# BL808 register map
File version: 0.1
Registers are access not given, no defined reset value unless marked. A register's access mark holds for its fields unless they carry their own. Offsets are from the block's base; [hi:lo] are bit positions.

## CSI
Base 0x3001A000
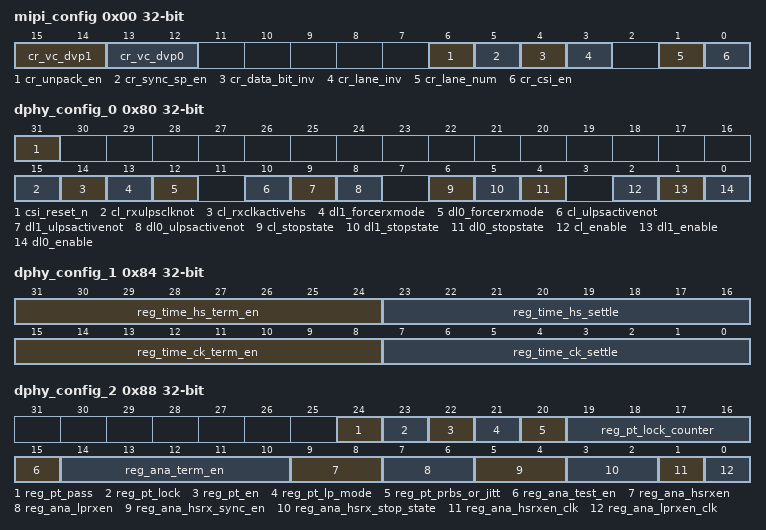
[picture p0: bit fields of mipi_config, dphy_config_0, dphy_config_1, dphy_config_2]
0x00 mipi_config
  [15:14] cr_vc_dvp1 rw — Virtual Channel number for DVP port 1
  [13:12] cr_vc_dvp0 rw — Virtual Channel number for DVP port 0
  [6] cr_unpack_en rw — Enable signal for data-unpack function 1'b0: Unpack disabled, DVP output is 8-bit valid (byte-in-byte-out) 1'b1: Unpack enabled, DVP output format depends on packet data type (RAW 8/10/12/14)
  [5] cr_sync_sp_en rw — Enable signal for sync short packets (FS/FE/LS/LE) to be received into gnr_data_buf
  [4] cr_data_bit_inv rw — Controls the bit ordering of PPI I/F data byte, which should be set to little-endian (MSB [7]) 1'b0: Not inversed 1'b1: Inversed
  [3] cr_lane_inv rw — Lane inverse 1'b0: Lane0 & Lane1 NOT inversed 1'b1: Lane0 & Lane1 inversed
  [1] cr_lane_num rw — Lane number configuration 1'b0: 1-lane MIPI RX 1'b1: 2-lane MIPI RX
  [0] cr_csi_en rw — Enable signal of MIPI receiving function
0x10 csi_int_status
  [5:0] csi_int_status ro — [5]: PHY HS SoT Sync Error [4]: PHY HS SoT Error [3]: CRC Error [2]: ECC Error [1]: Lane Merging Error [0]: Generic Packet Interrupt
0x14 csi_int_mask
  [5:0] csi_int_mask rw — [5]: PHY HS SoT Sync Error [4]: PHY HS SoT Error [3]: CRC Error [2]: ECC Error [1]: Lane Merging Error [0]: Generic Packet Interrupt
0x18 csi_int_clear
  [5:0] csi_int_clear write-once — [5]: PHY HS SoT Sync Error [4]: PHY HS SoT Error [3]: CRC Error [2]: ECC Error [1]: Lane Merging Error [0]: Generic Packet Interrupt
0x1C csi_int_enable
  [5:0] csi_int_enable rw — [5]: PHY HS SoT Sync Error [4]: PHY HS SoT Error [3]: CRC Error [2]: ECC Error [1]: Lane Merging Error [0]: Generic Packet Interrupt
0x20 gnr_buf_status
  [3:0] st_gnr_fifo_cnt ro — Generic Packet FIFO count
0x24 gnr_buf_rdata ro
  [31:0] gnr_buf_rdata — Generic Packet FIFO read port
0x80 dphy_config_0
  [31] csi_reset_n rw — MIPI CSI D-PHY reset pin
  [15] cl_rxulpsclknot ro — Receiver Ultra-Low Power State on clock lane
  [14] cl_rxclkactivehs ro — Receiver clock active
  [13] dl1_forcerxmode rw — Force Lane1 to Re-Initialize
  [12] dl0_forcerxmode rw — Force Lane0 to Re-Initialize
  [10] cl_ulpsactivenot ro — Clock lane is NOT in the ULP state
  [9] dl1_ulpsactivenot ro — Data lane1 is NOT in the ULP state
  [8] dl0_ulpsactivenot ro — Data lane0 is NOT in the ULP state
  [6] cl_stopstate ro — Clock lane is in Stop state
  [5] dl1_stopstate ro — Data lane1 is in Stop state
  [4] dl0_stopstate ro — Data lane0 is in Stop state
  [2] cl_enable rw — Clock lane enable
  [1] dl1_enable rw — Data lane1 enable
  [0] dl0_enable rw — Data lane0 enable
0x84 dphy_config_1 rw
  [31:24] reg_time_hs_term_en — MIPI CSI D-PHY control register - reg_time_hs_term_en (2x T_datarate), txclkesc: 40M, datarate: 800Mbps
  [23:16] reg_time_hs_settle — MIPI CSI D-PHY control register - reg_time_hs_settle (2x T_datarate)
  [15:8] reg_time_ck_term_en — MIPI CSI D-PHY control register - reg_time_ck_term_en (tx_clk_esc)
  [7:0] reg_time_ck_settle — MIPI CSI D-PHY control register - reg_time_ck_settle (tx_clk_esc)
0x88 dphy_config_2
  [24] reg_pt_pass ro — MIPI CSI D-PHY control register - reg_pt_pass
  [23] reg_pt_lock ro — MIPI CSI D-PHY control register - reg_pt_lock
  [22] reg_pt_en rw — MIPI CSI D-PHY control register - reg_pt_en
  [21] reg_pt_lp_mode rw — MIPI CSI D-PHY control register - reg_pt_lp_mode
  [20] reg_pt_prbs_or_jitt rw — MIPI CSI D-PHY control register - reg_pt_prbs_or_jitt
  [19:16] reg_pt_lock_counter rw — MIPI CSI D-PHY control register - reg_pt_lock_counter
  [15] reg_ana_test_en rw — MIPI CSI D-PHY control register - reg_ana_test_en
  [14:10] reg_ana_term_en rw — MIPI CSI D-PHY control register - reg_ana_term_en
  [9:8] reg_ana_hsrxen rw — MIPI CSI D-PHY control register - reg_ana_hsrxen
  [7:6] reg_ana_lprxen rw — MIPI CSI D-PHY control register - reg_ana_lprxen
  [5:4] reg_ana_hsrx_sync_en rw — MIPI CSI D-PHY control register - reg_ana_hsrx_sync_en
  [3:2] reg_ana_hsrx_stop_state rw — MIPI CSI D-PHY control register - reg_ana_hsrx_stop_state
  [1] reg_ana_hsrxen_clk rw — MIPI CSI D-PHY control register - reg_ana_hsrxen_clk
  [0] reg_ana_lprxen_clk rw — MIPI CSI D-PHY control register - reg_ana_lprxen_clk
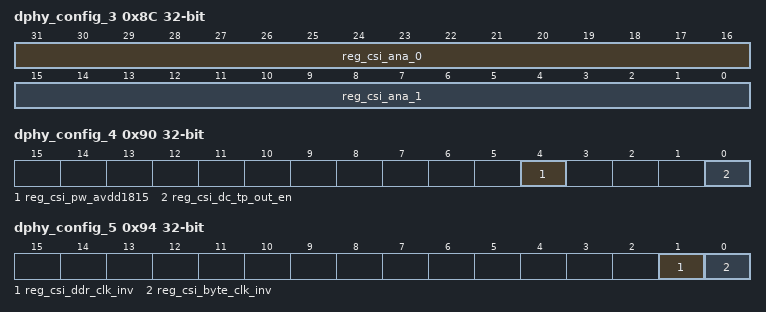
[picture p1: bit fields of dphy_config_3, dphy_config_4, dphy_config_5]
0x8C dphy_config_3 rw
  [31:16] reg_csi_ana_0 — MIPI CSI D-PHY control register - reg_csi_ana_0
  [15:0] reg_csi_ana_1 — MIPI CSI D-PHY control register - reg_csi_ana_1
0x90 dphy_config_4
  [4] reg_csi_pw_avdd1815 rw — 0: power switch on
  [0] reg_csi_dc_tp_out_en rw
0x94 dphy_config_5
  [1] reg_csi_ddr_clk_inv rw, [0] reg_csi_byte_clk_inv rw
0xFC dummy_reg rw
  [31:0] dummy_reg — Dummy registers
